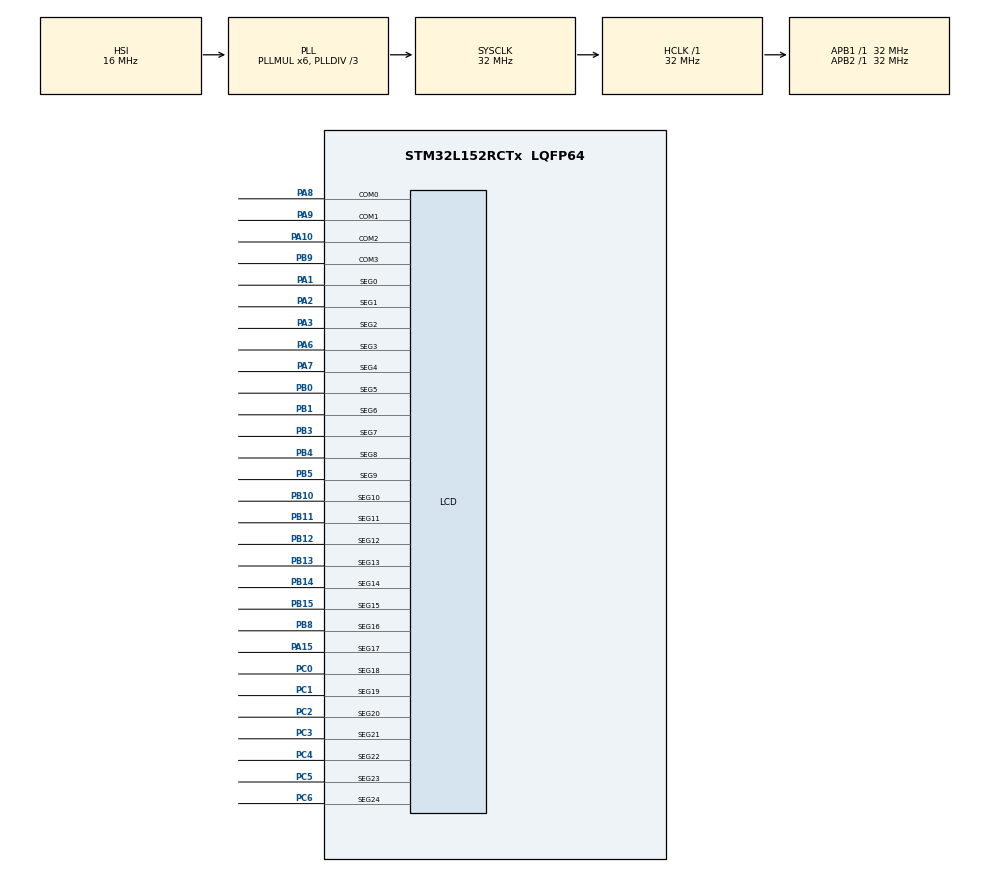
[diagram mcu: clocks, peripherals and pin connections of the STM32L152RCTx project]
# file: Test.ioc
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Mcu.Family=STM32L1
Mcu.Name=STM32L152RCTx
Mcu.Package=LQFP64
NVIC.PriorityGroup=NVIC_PRIORITYGROUP_0
PA1.Mode=SEG0
PA1.Signal=LCD_SEG0
PA10.Mode=1/4 Duty Cycle
PA10.Signal=LCD_COM2
PA15.Mode=SEG17
PA15.Signal=LCD_SEG17
PA2.Mode=SEG1
PA2.Signal=LCD_SEG1
PA3.Mode=SEG2
PA3.Signal=LCD_SEG2
PA6.Mode=SEG3
PA6.Signal=LCD_SEG3
PA7.Mode=SEG4
PA7.Signal=LCD_SEG4
PA8.Mode=1/4 Duty Cycle
PA8.Signal=LCD_COM0
PA9.Mode=1/4 Duty Cycle
PA9.Signal=LCD_COM1
PB0.Mode=SEG5
PB0.Signal=LCD_SEG5
PB1.Mode=SEG6
PB1.Signal=LCD_SEG6
PB10.Mode=SEG10
PB10.Signal=LCD_SEG10
PB11.Mode=SEG11
PB11.Signal=LCD_SEG11
PB12.Mode=SEG12
PB12.Signal=LCD_SEG12
PB13.Mode=SEG13
PB13.Signal=LCD_SEG13
PB14.Mode=SEG14
PB14.Signal=LCD_SEG14
PB15.Mode=SEG15
PB15.Signal=LCD_SEG15
PB3.Mode=SEG7
PB3.Signal=LCD_SEG7
PB4.Mode=SEG8
PB4.Signal=LCD_SEG8
PB5.Mode=SEG9
PB5.Signal=LCD_SEG9
PB8.Mode=SEG16
PB8.Signal=LCD_SEG16
PB9.Mode=1/4 Duty Cycle
PB9.Signal=LCD_COM3
PC0.Mode=SEG18
PC0.Signal=LCD_SEG18
PC1.Mode=SEG19
PC1.Signal=LCD_SEG19
PC2.Mode=SEG20
PC2.Signal=LCD_SEG20
PC3.Mode=SEG21
PC3.Signal=LCD_SEG21
PC4.Mode=SEG22
PC4.Signal=LCD_SEG22
PC5.Mode=SEG23
PC5.Signal=LCD_SEG23
PC6.Mode=SEG24
PC6.Signal=LCD_SEG24
PH0-OSC_IN.Mode=HSE-External-Oscillator
PH0-OSC_IN.Signal=RCC_OSC_IN
PH1-OSC_OUT.Mode=HSE-External-Oscillator
PH1-OSC_OUT.Signal=RCC_OSC_OUT
ProjectManager.HeapSize=0x200
ProjectManager.StackSize=0x400
ProjectManager.TargetToolchain=MDK-ARM V5
RCC.48MHZClocksFreq_Value=48000000
RCC.AHBFreq_Value=32000000
RCC.APB1Freq_Value=32000000
RCC.APB1TimFreq_Value=32000000
RCC.APB2Freq_Value=32000000
RCC.APB2TimFreq_Value=32000000
RCC.HCLKFreq_Value=32000000
RCC.HSE_VALUE=2000000
RCC.HSI_VALUE=16000000
RCC.LSE_VALUE=32768
RCC.MSI_VALUE=2097000
RCC.PLLDIV=RCC_PLL_DIV3
RCC.PLLMUL=RCC_PLL_MUL6
RCC.RTCClockSelection=RCC_RTCCLKSOURCE_HSE_DIV2
RCC.RTCClockSelectionVirtual=RCC_RTCCLKSOURCE_LSE
RCC.SYSCLKFreq_VALUE=32000000
RCC.SYSCLKSource=RCC_SYSCLKSOURCE_PLLCLK
RCC.USBOutput=48000000
RCC.VCOOutputFreq_Value=96000000
VP_LCD_LCD_mux.Mode=Multiplex
board=32L152CDISCOVERY

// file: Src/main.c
/* USER CODE BEGIN Header */
/**
  ******************************************************************************
  * @file           : main.c
  * @brief          : Main program body
  ******************************************************************************
  * @attention
  *
  * <h2><center>&copy; Copyright (c) 2019 STMicroelectronics.
  * All rights reserved.</center></h2>
  *
  * This software component is licensed by ST under BSD 3-Clause license,
  * the "License"; You may not use this file except in compliance with the
  * License. You may obtain a copy of the License at:
  *                        opensource.org/licenses/BSD-3-Clause
  *
  ******************************************************************************
  */
/* USER CODE END Header */

#include "main.h"

LCD_HandleTypeDef hlcd;

void SystemClock_Config(void);
static void MX_GPIO_Init(void);
static void MX_LCD_Init(void);

/* USER CODE BEGIN 0 */
void gpio(void);
void controller(void);
/* USER CODE END 0 */

int main(void)
{

  /* MCU Configuration--------------------------------------------------------*/

  /* Reset of all peripherals, Initializes the Flash interface and the Systick. */
  HAL_Init();

  /* Configure the system clock */
  SystemClock_Config();

  /* USER CODE BEGIN SysInit */
	LCD_GLASS_InitGpio();
	LCD_GLASS_InitController();

  /* USER CODE END SysInit */

  /* Initialize all configured peripherals */
  MX_GPIO_Init();
  //MX_LCD_Init();
  /* USER CODE BEGIN 2 */

	HAL_Delay(123);
	char* str = "1234567890";
	//LCD_GLASS_DisplayString((uint8_t*)str);
	//LCD_GLASS_DisplayWholeString((uint8_t*)str, strlen(str), 500);
	LCD_GLASS_Tiker((uint8_t*)str, strlen(str), 500, 2000, 0, NULL);
//
  /* USER CODE END 2 */

  /* Infinite loop */
  while (1)
  {

  }
}

void SystemClock_Config(void)
{
  RCC_OscInitTypeDef RCC_OscInitStruct = {0};
  RCC_ClkInitTypeDef RCC_ClkInitStruct = {0};
  RCC_PeriphCLKInitTypeDef PeriphClkInit = {0};

  /** Configure the main internal regulator output voltage
  */
  __HAL_PWR_VOLTAGESCALING_CONFIG(PWR_REGULATOR_VOLTAGE_SCALE1);
  /** Initializes the CPU, AHB and APB busses clocks
  */
  RCC_OscInitStruct.OscillatorType = RCC_OSCILLATORTYPE_HSI|RCC_OSCILLATORTYPE_HSE;
  RCC_OscInitStruct.HSEState = RCC_HSE_ON;
  RCC_OscInitStruct.HSIState = RCC_HSI_ON;
  RCC_OscInitStruct.HSICalibrationValue = RCC_HSICALIBRATION_DEFAULT;
  RCC_OscInitStruct.PLL.PLLState = RCC_PLL_ON;
  RCC_OscInitStruct.PLL.PLLSource = RCC_PLLSOURCE_HSI;
  RCC_OscInitStruct.PLL.PLLMUL = RCC_PLL_MUL6;
  RCC_OscInitStruct.PLL.PLLDIV = RCC_PLL_DIV3;
  if (HAL_RCC_OscConfig(&RCC_OscInitStruct) != HAL_OK)
  {
    Error_Handler();
  }
  /** Initializes the CPU, AHB and APB busses clocks
  */
  RCC_ClkInitStruct.ClockType = RCC_CLOCKTYPE_HCLK|RCC_CLOCKTYPE_SYSCLK
                              |RCC_CLOCKTYPE_PCLK1|RCC_CLOCKTYPE_PCLK2;
  RCC_ClkInitStruct.SYSCLKSource = RCC_SYSCLKSOURCE_PLLCLK;
  RCC_ClkInitStruct.AHBCLKDivider = RCC_SYSCLK_DIV1;
  RCC_ClkInitStruct.APB1CLKDivider = RCC_HCLK_DIV1;
  RCC_ClkInitStruct.APB2CLKDivider = RCC_HCLK_DIV1;

  if (HAL_RCC_ClockConfig(&RCC_ClkInitStruct, FLASH_LATENCY_1) != HAL_OK)
  {
    Error_Handler();
  }
  PeriphClkInit.PeriphClockSelection = RCC_PERIPHCLK_LCD;
  PeriphClkInit.LCDClockSelection = RCC_RTCCLKSOURCE_HSE_DIV2;

  if (HAL_RCCEx_PeriphCLKConfig(&PeriphClkInit) != HAL_OK)
  {
    Error_Handler();
  }
}

static void MX_LCD_Init(void)
{

  hlcd.Instance = LCD;
  hlcd.Init.Prescaler = LCD_PRESCALER_1;
  hlcd.Init.Divider = LCD_DIVIDER_16;
  hlcd.Init.Duty = LCD_DUTY_1_4;
  hlcd.Init.Bias = LCD_BIAS_1_4;
  hlcd.Init.VoltageSource = LCD_VOLTAGESOURCE_INTERNAL;
  hlcd.Init.Contrast = LCD_CONTRASTLEVEL_0;
  hlcd.Init.DeadTime = LCD_DEADTIME_0;
  hlcd.Init.PulseOnDuration = LCD_PULSEONDURATION_0;
  hlcd.Init.MuxSegment = LCD_MUXSEGMENT_ENABLE;
  hlcd.Init.BlinkMode = LCD_BLINKMODE_OFF;
  hlcd.Init.BlinkFrequency = LCD_BLINKFREQUENCY_DIV8;
  if (HAL_LCD_Init(&hlcd) != HAL_OK)
  {
    Error_Handler();
  }

}

static void MX_GPIO_Init(void)
{

  /* GPIO Ports Clock Enable */
  __HAL_RCC_GPIOH_CLK_ENABLE();
  __HAL_RCC_GPIOC_CLK_ENABLE();
  __HAL_RCC_GPIOA_CLK_ENABLE();
  __HAL_RCC_GPIOB_CLK_ENABLE();

}

void Error_Handler(void)
{
}

/************************ (C) COPYRIGHT STMicroelectronics *****END OF FILE****/
